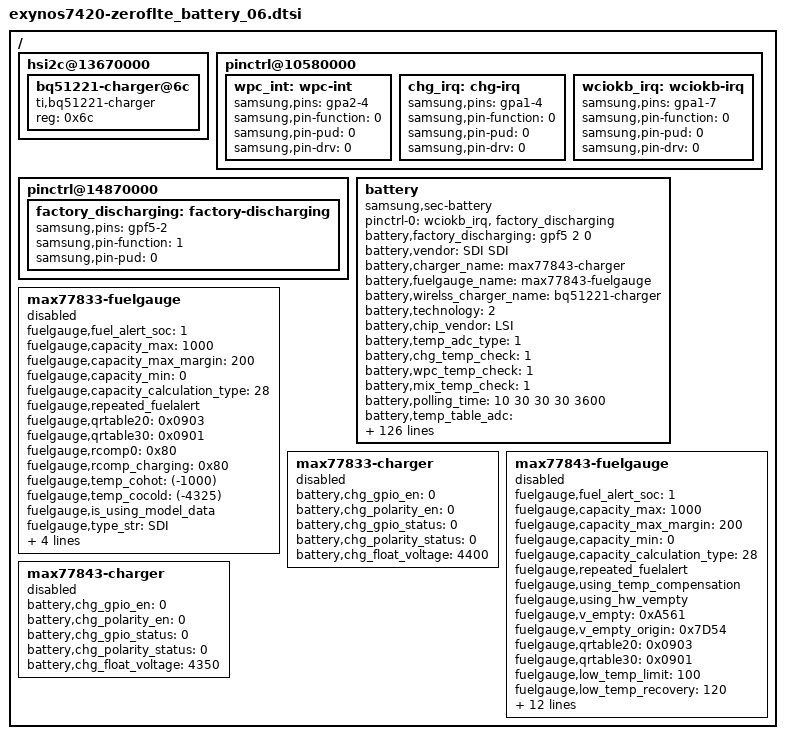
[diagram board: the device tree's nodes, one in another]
/*
 * SAMSUNG UNIVERSAL5433 board device tree source
 *
 * Copyright (c) 2013 Samsung Electronics Co., Ltd.
 *		http://www.samsung.com
 *
 * This program is free software; you can redistribute it and/or modify
 * it under the terms of the GNU General Public License version 2 as
 * published by the Free Software Foundation.
*/

/ {
	hsi2c@13670000 { /* hsi2c5 */
		status = "okay";

		bq51221-charger@6c {
			compatible = "ti,bq51221-charger";
			reg = <0x6c>;
			status = "okay";
		};
	};

	pinctrl@10580000 {
		wpc_int: wpc-int {
			samsung,pins = "gpa2-4";
			samsung,pin-function = <0>;
			samsung,pin-pud = <0>;
			samsung,pin-drv = <0>;
		};
		chg_irq: chg-irq {
			 samsung,pins = "gpa1-4";
			 samsung,pin-function = <0>;
			 samsung,pin-pud = <0>;
			 samsung,pin-drv = <0>;
		};

		wciokb_irq: wciokb-irq {
			 samsung,pins = "gpa1-7";
			 samsung,pin-function = <0>;
			 samsung,pin-pud = <0>;
			 samsung,pin-drv = <0>;
		};

	};

	pinctrl@14870000 {
		factory_discharging: factory-discharging {
			samsung,pins = "gpf5-2";
			samsung,pin-function = <1>;
			samsung,pin-pud = <0>;
		};

	};

	battery {
		status = "okay";

		pinctrl-names = "default";
		pinctrl-0 = <&wciokb_irq &factory_discharging>;

		battery,factory_discharging = <&gpf5 2 0>;

		compatible = "samsung,sec-battery";
		battery,vendor = "SDI SDI";
		battery,charger_name = "max77843-charger";
		battery,fuelgauge_name = "max77843-fuelgauge";
		battery,wirelss_charger_name = "bq51221-charger";
		battery,technology = <2>; /* POWER_SUPPLY_TECHNOLOGY_LION */
		/* .temp_cohot = -1000; */
		/* .temp_cocold = -4325; */

		battery,chip_vendor = "LSI";
		battery,temp_adc_type = <1>; /* SEC_BATTERY_ADC_TYPE_AP */

		battery,chg_temp_check = <1>;
		battery,wpc_temp_check = <1>;
		battery,mix_temp_check = <1>;

		battery,polling_time = <10 30 30 30 3600>;

		battery,temp_table_adc = <297 347 406 476 564 642 754 828 879 934 1030 1127 1194 1265 1370 1484 1573 1657
						1787 1922 2016 2253 2482 2706 2927 3007 3123 3228 3297 3361 3445 3585 3710>;
		battery,temp_table_data = <900 850 800 750 700 650 600 570 550 530 500 470 450 430 400 370 350 330
						300 270 250 200 150 100 50 30 0 (-30) (-50) (-70) (-100) (-150) (-200)>;

		battery,chg_temp_table_adc = <368 433 509 600 708 779 829 879 972 1067 1132 1200 1301 1412 1501
						1583 1710 1843 1937 2175 2408 2634 2856 2944 3066 3176 3249 3316 3407 3547 3672>;
		battery,chg_temp_table_data = <800 750 700 650 600 570 550 530 500 470 450 430 400 370 350
						330 300 270 250 200 150 100 50 30 0 (-30) (-50) (-70) (-100) (-150) (-200)>;

		battery,wpc_temp_table_adc = <368 433 509 601 708 779 829 880 972 1067 1132 1200 1301 1412 1501
						1583 1710 1842 1937 2174 2407 2632 2855 2942 3060 3170 3244 3309 3401 3541 3666>;
		battery,wpc_temp_table_data = <800 750 700 650 600 570 550 530 500 470 450 430 400 370 350
						330 300 270 250 200 150 100 50 30 0 (-30) (-50) (-70) (-100) (-150) (-200)>;

		battery,input_current_limit = <1800 0 0 1800 460 900 1000 460 1000 0 820 820 820 1900 1800 0 0 400 700 1300 300 1000 1500 0 1667 1000 1667 80 1800 1667 1400 1000 1000 1800>;
		battery,fast_charging_current = <2000 0 0 2000 460 1200 1000 460 1200 0 1150 1150 1150 1600 2000 0 0 400 700 1300 300 1000 1500 0 2000 1000 2000 80 1800 1000 1400 0 1000 2000>;
		battery,full_check_current_1st = <350 0 0 350 350 350 350 350 350 0 350 350 350 350 350 0 0 350 350 350 350 350 350 0 350 350 350 350 0 350 350 350 0 350 350 350 350 350 350 350>;
		battery,full_check_current_2nd = <150 0 0 150 150 150 150 150 150 0 150 150 150 150 150 0 0 150 150 150 150 150 150 0 150 150 150 150 0 150 150 150 0 150 150 150 150 150 150 150>;

		battery,wireless_cc_cv = <86>;
		battery,inbat_voltage = <1>;

		battery,inbat_voltage_table_adc = <2838 2811 2796 2763 2737 2708 2681 2638 2597 2568
						2549 2524 2506 2483 2434 2403 2365 2337 2316 2287 2271>;
		battery,inbat_voltage_table_data = <438 435 430 425 420 415 410 405 400 395
						390 385 380 375 370 365 360 355 350 345 340>;

		battery,adc_check_count = <5>;

		battery,cable_check_type = <4>; /* SEC_BATTERY_CABLE_CHECK_PSY */
		battery,cable_source_type = <1>; /* SEC_BATTERY_CABLE_SOURCE_EXTERNAL */
		battery,event_waiting_time = <600>;
		battery,polling_type = <1>; /* SEC_BATTERY_MONITOR_ALARM */
		battery,monitor_initial_count = <0>;

		battery,battery_check_type = <0>;
		battery,check_count = <0>;
		battery,check_adc_max = <1440>;
		battery,check_adc_min = <0>;

		battery,ovp_uvlo_check_type = <3>; /* SEC_BATTERY_OVP_UVLO_CHGPOLLING */

		battery,thermal_source = <2>; /* SEC_BATTERY_THERMAL_SOURCE_ADC */

		battery,temp_check_type = <2>; /* _BATTERY_TEMP_CHECK_TEMP */
		battery,temp_check_count = <1>;
		battery,temp_highlimit_threshold_event = <800>;
		battery,temp_highlimit_recovery_event = <750>;
		battery,temp_high_threshold_event = <500>;
		battery,temp_high_recovery_event = <450>;
		battery,temp_low_threshold_event = <0>;
		battery,temp_low_recovery_event = <50>;
		battery,temp_highlimit_threshold_normal = <800>;
		battery,temp_highlimit_recovery_normal = <750>;
		battery,temp_high_threshold_normal = <500>;
		battery,temp_high_recovery_normal = <450>;
		battery,temp_low_threshold_normal = <0>;
		battery,temp_low_recovery_normal = <50>;
		battery,temp_highlimit_threshold_lpm = <800>;
		battery,temp_highlimit_recovery_lpm = <750>;
		battery,temp_high_threshold_lpm = <500>;
		battery,temp_high_recovery_lpm = <450>;
		battery,temp_low_threshold_lpm = <0>;
		battery,temp_low_recovery_lpm = <50>;
		battery,wpc_high_threshold_normal = <450>;
		battery,wpc_high_recovery_normal = <400>;
		battery,wpc_low_threshold_normal = <0>;
		battery,wpc_low_recovery_normal = <50>;		
		battery,full_check_type = <7>; /* SEC_BATTERY_FULLCHARGED_CHGPSY */
		battery,full_check_type_2nd = <7>; /* SEC_BATTERY_FULLCHARGED_CHGPSY */
		battery,full_check_count = <1>;
		battery,chg_gpio_full_check = <0>;
		battery,chg_polarity_full_check = <1>;

		battery,chg_high_temp_1st = <500>;
		battery,chg_high_temp_2nd = <500>;
		battery,chg_high_temp_recovery = <495>;
		battery,chg_charging_limit_current = <1100>;
		battery,chg_charging_limit_current_2nd = <1100>;
		battery,chg_skip_check_capacity = <10>;
		battery,chg_skip_check_time = <600>;

		battery,wpc_high_temp = <400>;
		battery,wpc_high_temp_recovery = <390>;
		battery,wpc_charging_limit_current = <450>;

		battery,wpc_delayed_current_en;
		battery,wpc_delayed_current = <860>;
		battery,wpc_delayed_current_time = <420>;

		battery,mix_high_tbat = <400>;
		battery,mix_high_tchg = <500>;
		battery,mix_high_tbat_recov = <370>;
		battery,mix_input_limit_current = <100>;
		battery,mix_high_tbat_hv = <420>;
		battery,mix_high_tchg_hv = <500>;
		battery,mix_high_tbat_recov_hv = <390>;
		battery,mix_input_limit_current_hv = <100>;

		/* SEC_BATTERY_FULL_CONDITION_SOC |
		   SEC_BATTERY_FULL_CONDITION_NOTIMEFULL |
		   SEC_BATTERY_FULL_CONDITION_VCELL */
		battery,full_condition_type = <13>;
		battery,full_condition_soc = <93>;
		battery,full_condition_vcell = <4250>;

		battery,recharge_check_count = <2>;
		battery,recharge_condition_type = <4>; /* SEC_BATTERY_RECHARGE_CONDITION_VCELL */
		battery,recharge_condition_soc = <98>;
		battery,recharge_condition_vcell = <4300>;

		battery,charging_total_time = <21600>;
		battery,hv_charging_total_time = <10800>;
		battery,normal_charging_total_time = <18000>;
		battery,usb_charging_total_time = <36000>;
		battery,recharging_total_time = <5400>;
		battery,charging_reset_time = <0>;

		battery,chg_float_voltage = <4350>;

		battery,self_discharging_en;
		battery,force_discharging_limit = <650>;
		battery,force_discharging_recov = <550>;
		battery,self_discharging_voltage_limit = <4250>;
		battery,discharging_adc_max = <2600>;
		battery,discharging_adc_min = <1700>;
		battery,discharging_ntc_limit = <2750>;

		battery,swelling_high_temp_block = <410>;
		battery,swelling_high_temp_recov = <360>;
		battery,swelling_low_temp_block = <100>;
		battery,swelling_low_temp_recov = <150>;
		battery,swelling_chg_current = <1100>;
		battery,swelling_drop_float_voltage = <4150>;
		battery,swelling_high_rechg_voltage = <4100>;
		battery,swelling_low_rechg_voltage = <4000>;
		battery,swelling_block_time = <600>;
		battery,swelling_wc_chg_current = <750>;	/* 0.8C * 0.3C */

		/* cycle, chg_float_voltage, recharge_condition_vcell, full_condition_vcell, full_condition_soc */
		battery,age_data = <0 43500 4300 4250 93
			200 43250 4275 4225 92
			250 43125 4262 4212 91
			300 42875 4237 4187 90
			1000 42375 4187 4137 89>;

		io-channels = <&exynos_adc 1>, <&exynos_adc 3>, <&exynos_adc 6>, <&exynos_adc 5>, <&exynos_adc 7>;
		io-channel-names = "adc-temp", "chg-adc-temp", "in-bat-adc", "discharging-check-adc", "ntc-check-adc";
		#io-channel-cells = <5>;
		io-channel-ranges;

		battery,cisd_cap_high_thr = <3550>;
		battery,cisd_cap_low_thr = <3050>;
		battery,cisd_cap_limit = <2805>;
	};

	max77833-fuelgauge {
		status = "disable";
		fuelgauge,fuel_alert_soc = <1>;
		fuelgauge,capacity_max = <1000>;
		fuelgauge,capacity_max_margin = <200>;
		fuelgauge,capacity_min = <0>;
		fuelgauge,capacity_calculation_type = <28>;
		fuelgauge,repeated_fuelalert;
		fuelgauge,qrtable20 = <0x0903>;
		fuelgauge,qrtable30 = <0x0901>;
		fuelgauge,rcomp0 = <0x80>;
		fuelgauge,rcomp_charging = <0x80>;
		fuelgauge,temp_cohot = <(-1000)>;
		fuelgauge,temp_cocold = <(-4325)>;
		fuelgauge,is_using_model_data;
		fuelgauge,type_str = "SDI";
		fuelgauge,capacity = <0x1B5F>;
		fuelgauge,low_battery_comp_voltage = <3600>;
		fuelgauge,low_battery_table = <(-5000) 0 0 (-1250) 0 3320 (-750) 97 3451 (-100) 96 3461 0 0 3456>;

	};
	max77833-charger {
	        status = "disable";
		battery,chg_gpio_en = <0>;
		battery,chg_polarity_en = <0>;
		battery,chg_gpio_status = <0>;
		battery,chg_polarity_status = <0>;
		battery,chg_float_voltage = <4400>;
	};

	max77843-fuelgauge {
		status = "disable";
		fuelgauge,fuel_alert_soc = <1>;
		fuelgauge,capacity_max = <1000>;
		fuelgauge,capacity_max_margin = <200>;
		fuelgauge,capacity_min = <0>;
		fuelgauge,capacity_calculation_type = <28>;
		fuelgauge,repeated_fuelalert;
		fuelgauge,using_temp_compensation;
		fuelgauge,using_hw_vempty;
		fuelgauge,v_empty = <0xA561>; /* Empty: 3260mV, Recover: 3480mV */
		fuelgauge,v_empty_origin = <0x7D54>; /* Empty: 2500mV, Recover: 3360mV */
		fuelgauge,qrtable20 = <0x0903>;
		fuelgauge,qrtable30 = <0x0901>;
		fuelgauge,low_temp_limit = <100>;
		fuelgauge,low_temp_recovery = <120>;
		fuelgauge,temp_cohot = <0x1B45>;
		fuelgauge,temp_cocold = <0x194D>;
		fuelgauge,rcomp0 = <0x80>;
		fuelgauge,rcomp_charging = <0x80>;
		fuelgauge,is_using_model_data;
		fuelgauge,type_str = "SDI";
		fuelgauge,capacity = <0x1B5F>;
		fuelgauge,low_battery_comp_voltage = <3600>;
		fuelgauge,low_battery_table = <(-5000) 0 0 (-1250) 0 3320 (-750) 97 3451 (-100) 96 3461 0 0 3456>;
		fuelgauge,cv_data = <
			2488	829	1809
			2409	832	1796
			2327	837	1769
			2272	840	1743
			2182	846	1721
			2104	850	1690
			2038	854	1670
			1950	859	1640
			1904	861	1622
			1838	865	1594
			1797	867	1576
			1749	870	1560
			1703	873	1531
			1683	873	1525
			1667	875	1515
			1660	875	1512
			1653	876	1509
			1615	878	1502
			1580	880	1483
			1553	881	1463
			1544	882	1458
			1520	883	1451
			1477	886	1424
			1431	888	1409
			1396	891	1383
			1347	894	1361
			1299	896	1332
			1267	898	1315
			1231	902	1288
			1202	904	1263
			1148	906	1243
			1109	909	1213
			1067	911	1185
			1031	914	1156
			1013	915	1140
			975	917	1111
			961	919	1084
			921	921	1064
			892	923	1038
			887	923	1019
			863	925	1004
			833	927	976
			808	929	946
			787	930	918
			780	931	904
			764	932	895
			744	934	864
			730	935	846
			715	936	828
			693	937	800
			681	938	783
			666	940	752
			651	941	735
			640	942	712
			628	945	697
			622	946	679
			618	947	664
			600	950	646
			596	951	627
			589	953	614
			584	953	601
			576	956	572
			577	957	553
			562	958	535
			511	968	506
			505	969	487
			493	971	464
			492	972	435
			484	973	417
			480	975	398
			474	976	380
			470	977	364
			462	977	355
			456	978	336
			452	979	329
			446	981	303
			437	982	282
			429	984	255
			423	985	242
			422	986	229
			414	987	211
			411	988	199
			405	989	191
			397	990	171
			391	991	140
			387	992	126
			384	993	107
			372	995	84
			364	997	54
			356	998	26
			356	998	13
			0	1000	0
			>;
	};
	max77843-charger {
	        status = "disable";
		battery,chg_gpio_en = <0>;
		battery,chg_polarity_en = <0>;
		battery,chg_gpio_status = <0>;
		battery,chg_polarity_status = <0>;
		battery,chg_float_voltage = <4350>;
	};

};
